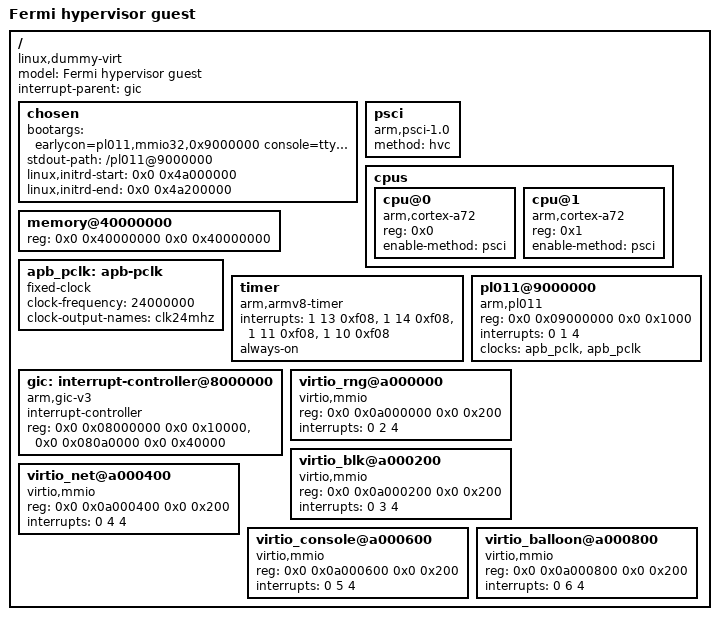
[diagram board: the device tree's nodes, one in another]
/dts-v1/;

/*
 * guest.dts — device tree for the Linux guest running under the Fermi
 * hypervisor. The guest sees 1 GiB of RAM at IPA 0x40000000, a PL011 UART at
 * 0x09000000 (mapped through stage-2 to the physical board UART), a GICv3, and
 * the architected timer. PSCI is routed over HVC to the hypervisor.
 *
 * Compiled to build/guest.dtb by the Makefile and loaded into guest RAM by
 * QEMU's generic loader.
 */

/ {
	#address-cells = <2>;
	#size-cells = <2>;
	compatible = "linux,dummy-virt";
	model = "Fermi hypervisor guest";
	interrupt-parent = <&gic>;

	chosen {
		bootargs = "earlycon=pl011,mmio32,0x9000000 console=ttyAMA0 nokaslr rdinit=/init";
		stdout-path = "/pl011@9000000";
		linux,initrd-start = <0x0 0x4a000000>;
		linux,initrd-end   = <0x0 0x4a200000>;
	};

	psci {
		compatible = "arm,psci-1.0", "arm,psci-0.2";
		method = "hvc";
	};

	cpus {
		#address-cells = <1>;
		#size-cells = <0>;

		cpu@0 {
			device_type = "cpu";
			compatible = "arm,cortex-a72";
			reg = <0x0>;
			enable-method = "psci";
		};

		cpu@1 {
			device_type = "cpu";
			compatible = "arm,cortex-a72";
			reg = <0x1>;
			enable-method = "psci";
		};
	};

	memory@40000000 {
		device_type = "memory";
		reg = <0x0 0x40000000 0x0 0x40000000>; /* 1 GiB */
	};

	apb_pclk: apb-pclk {
		compatible = "fixed-clock";
		#clock-cells = <0>;
		clock-frequency = <24000000>;
		clock-output-names = "clk24mhz";
	};

	timer {
		compatible = "arm,armv8-timer";
		interrupts = <1 13 0xf08>,
			     <1 14 0xf08>,
			     <1 11 0xf08>,
			     <1 10 0xf08>;
		always-on;
	};

	pl011@9000000 {
		compatible = "arm,pl011", "arm,primecell";
		reg = <0x0 0x09000000 0x0 0x1000>;
		interrupts = <0 1 4>;
		clocks = <&apb_pclk>, <&apb_pclk>;
		clock-names = "uartclk", "apb_pclk";
	};

	gic: interrupt-controller@8000000 {
		compatible = "arm,gic-v3";
		#interrupt-cells = <3>;
		#address-cells = <2>;
		#size-cells = <2>;
		ranges;
		interrupt-controller;
		reg = <0x0 0x08000000 0x0 0x10000>,   /* GICD */
		      <0x0 0x080a0000 0x0 0x40000>;    /* GICR (2 cores) */
	};

	/* Emulated virtio-rng (virtio-mmio, device id 4). The hypervisor traps
	 * this MMIO region and the device interrupt is SPI 2 (INTID 34). */
	virtio_rng@a000000 {
		compatible = "virtio,mmio";
		reg = <0x0 0x0a000000 0x0 0x200>;
		interrupts = <0 2 4>;
	};

	/* Emulated virtio-blk (virtio-mmio, device id 2) => /dev/vda. The device
	 * interrupt is SPI 3 (INTID 35). */
	virtio_blk@a000200 {
		compatible = "virtio,mmio";
		reg = <0x0 0x0a000200 0x0 0x200>;
		interrupts = <0 3 4>;
	};

	/* Emulated virtio-net (virtio-mmio, device id 1) => eth0. The hypervisor
	 * acts as the link peer: it answers ARP + ICMP echo so the guest can ping
	 * a hypervisor-emulated host. IRQ SPI 4 => INTID 36. */
	virtio_net@a000400 {
		compatible = "virtio,mmio";
		reg = <0x0 0x0a000400 0x0 0x200>;
		interrupts = <0 4 4>;
	};

	/* Emulated virtio-console (virtio-mmio, device id 3) => /dev/hvc0. The
	 * hypervisor forwards transmitted data to its own serial. IRQ SPI 5. */
	virtio_console@a000600 {
		compatible = "virtio,mmio";
		reg = <0x0 0x0a000600 0x0 0x200>;
		interrupts = <0 5 4>;
	};

	/* Emulated virtio-balloon (virtio-mmio, device id 5). The host inflates it
	 * via vmctl; the guest hands pages back. IRQ SPI 6 => INTID 38. */
	virtio_balloon@a000800 {
		compatible = "virtio,mmio";
		reg = <0x0 0x0a000800 0x0 0x200>;
		interrupts = <0 6 4>;
	};
};
